# APP_ECC_AGG register map
Vendor: Texas Instruments
Peripheral module from a debugger description file (folder xwrl64xx).
Registers are 32-bit, access per field, no defined reset value unless marked. A register's access mark holds for its fields unless they carry their own. Offsets are as the file gives them; lines under a group give offsets from that group; [hi:lo] are bit positions; {n}, {i} and the like mark numbered series; 'fields as' and 'values as' point back to an identical list; <NAME> marks a mode.

## APP_ECC_AGG
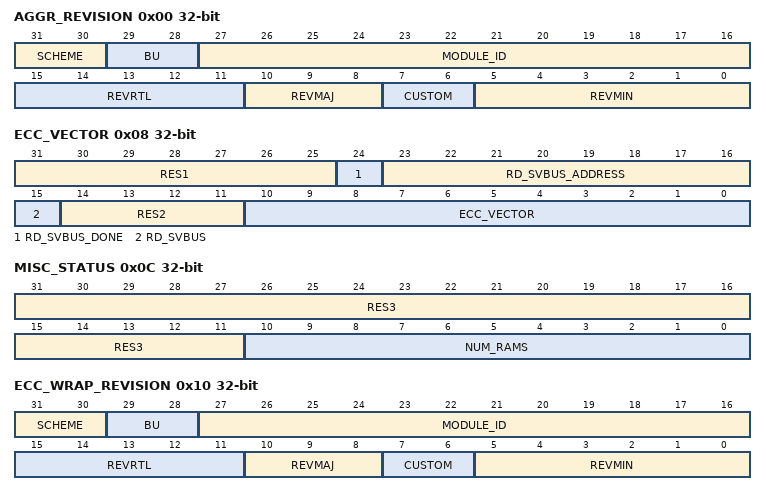
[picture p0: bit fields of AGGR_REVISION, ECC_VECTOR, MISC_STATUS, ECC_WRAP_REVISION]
0x00 AGGR_REVISION ro — Revision parameters
  [31:30] SCHEME — Scheme - (RO )
  [29:28] BU — bu - (RO )
  [27:16] MODULE_ID — Module ID - (RO )
  [15:11] REVRTL — RTL version - (RO )
  [10:8] REVMAJ — Major version - (RO )
  [7:6] CUSTOM — Custom version - (RO )
  [5:0] REVMIN — Minor version - (RO )
0x08 ECC_VECTOR
  [31:25] RES1 ro — RESERVE FIELD
  [24] RD_SVBUS_DONE ro — Status to indicate if read on serial VBUS is complete - (RO )
  [23:16] RD_SVBUS_ADDRESS rw — Read address - (RW )
  [15] RD_SVBUS rw — Write 1 to trigger a read on the serial VBUS - (RW )
  [14:11] RES2 ro — RESERVE FIELD
  [10:0] ECC_VECTOR rw — Value written to select the corresponding ECC RAM for control or status - (RW )
0x0C MISC_STATUS ro
  [31:11] RES3 — RESERVE FIELD
  [10:0] NUM_RAMS — Indicates the number of RAMS serviced by the ECC aggregator - (RO )
0x10 ECC_WRAP_REVISION ro — Revision parameters
  fields as AGGR_REVISION
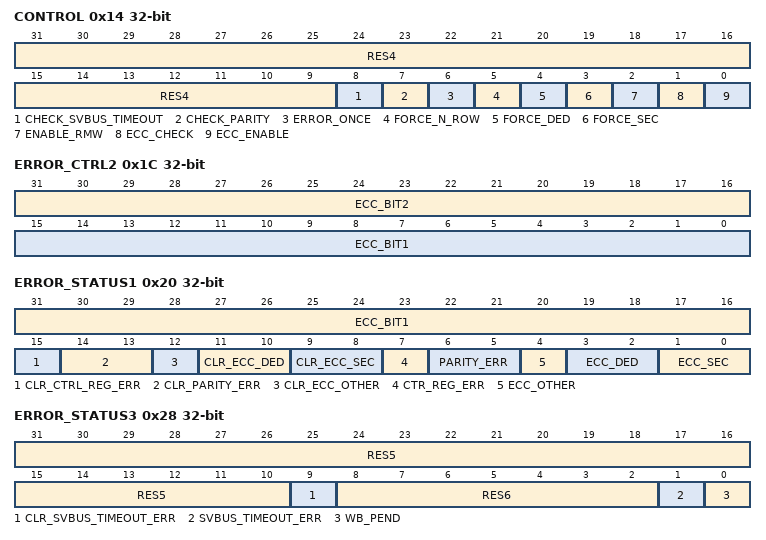
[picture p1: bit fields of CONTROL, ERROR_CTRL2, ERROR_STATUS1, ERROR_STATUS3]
0x14 CONTROL — ECC Control Register
  [31:9] RES4 ro — RESERVE FIELD
  [8] CHECK_SVBUS_TIMEOUT rw — check for svbus timeout errors - (RW )
  [7] CHECK_PARITY rw — check for parity errors - (RW )
  [6] ERROR_ONCE rw — Force Error only once - (RW )
  [5] FORCE_N_ROW rw — Force Error on any RAM read - (RW )
  [4] FORCE_DED rw — Force Double Bit Error - (RW )
  [3] FORCE_SEC rw — Force Single Bit Error - (RW )
  [2] ENABLE_RMW rw — Enable rmw - (RW )
  [1] ECC_CHECK rw — Enable ECC check - (RW )
  [0] ECC_ENABLE rw — Enable ECC - (RW )
0x18 ERROR_CTRL1 rw — ECC Error Control1 Register
  [31:0] ECC_ROW — Row address where single or double-bit error needs to be applied. This is ignored if force_n_row is set - (RW )
0x1C ERROR_CTRL2 rw — ECC Error Control2 Register
  [31:16] ECC_BIT2 — Data bit that needs to be flipped if double bit error needs to be forced - (RW )
  [15:0] ECC_BIT1 — Data bit that needs to be flipped when force_sec is set - (RW )
0x20 ERROR_STATUS1 — ECC Error Status1 Register
  [31:16] ECC_BIT1 ro — Data bit that corresponds to the single-bit error - (RO )
  [15] CLR_CTRL_REG_ERR rw — Clear control reg error Error Status you must also re write the contorl ergister itself to clear this - (RW )
  [14:13] CLR_PARITY_ERR rw — Clear parity Error Status - (RW decr)
  [12] CLR_ECC_OTHER rw — Clear other Error Status - (RW )
  [11:10] CLR_ECC_DED rw — Clear Double Bit Error Status - (RW decr)
  [9:8] CLR_ECC_SEC rw — Clear Single Bit Error Status - (RW decr)
  [7] CTR_REG_ERR rw — control register error pending Level interrupt - (RW
  [6:5] PARITY_ERR rw — Level parity error Error Status - (RW )
  [4] ECC_OTHER rw — successive single-bit errors have occurred while a writeback is still pending Level interrupt - (RW
  [3:2] ECC_DED rw — Level Double Bit Error Status - (RW incr)
  [1:0] ECC_SEC rw — Level Single Bit Error Status - (RW incr)
0x24 ERROR_STATUS2 ro — ECC Error Status2 Register
  [31:0] ECC_ROW — Row address where the single or double-bit error has occurred - (RO )
0x28 ERROR_STATUS3 — ECC Error Status3 Register
  [31:10] RES5 ro — RESERVE FIELD
  [9] CLR_SVBUS_TIMEOUT_ERR rw — Clear svbus timeout Error Status - (RW )
  [8:2] RES6 ro — RESERVE FIELD
  [1] SVBUS_TIMEOUT_ERR rw — Level svbus timeout error Error Status - (RW )
  [0] WB_PEND ro — delayed write back pending Status - (RO )
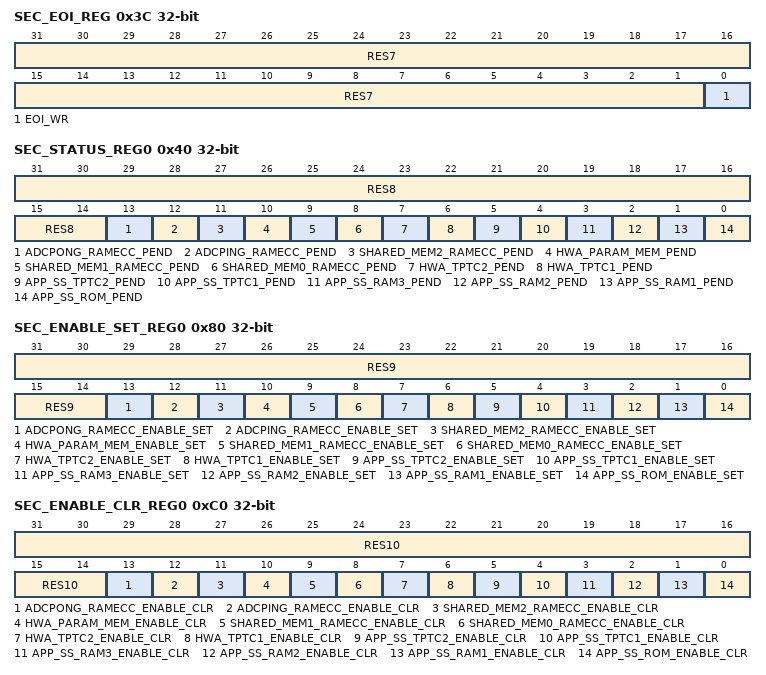
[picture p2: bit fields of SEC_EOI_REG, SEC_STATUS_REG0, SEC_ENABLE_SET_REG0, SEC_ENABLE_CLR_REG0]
0x3C SEC_EOI_REG — EOI Register
  [31:1] RES7 ro — RESERVE FIELD
  [0] EOI_WR rw — EOI Register - (RW )
0x40 SEC_STATUS_REG0 — Interrupt Status Register 0
  [31:14] RES8 ro — RESERVE FIELD
  [13] ADCPONG_RAMECC_PEND rw — Interrupt Pending Status for adcpong_ramecc_pend - (RW )
  [12] ADCPING_RAMECC_PEND rw — Interrupt Pending Status for adcping_ramecc_pend - (RW )
  [11] SHARED_MEM2_RAMECC_PEND rw — Interrupt Pending Status for shared_mem2_ramecc_pend - (RW )
  [10] HWA_PARAM_MEM_PEND rw — Interrupt Pending Status for hwa_param_mem_pend - (RW )
  [9] SHARED_MEM1_RAMECC_PEND rw — Interrupt Pending Status for shared_mem1_ramecc_pend - (RW )
  [8] SHARED_MEM0_RAMECC_PEND rw — Interrupt Pending Status for shared_mem0_ramecc_pend - (RW )
  [7] HWA_TPTC2_PEND rw — Interrupt Pending Status for hwa_tptc2_pend - (RW )
  [6] HWA_TPTC1_PEND rw — Interrupt Pending Status for hwa_tptc1_pend - (RW )
  [5] APP_SS_TPTC2_PEND rw — Interrupt Pending Status for app_ss_tptc2_pend - (RW )
  [4] APP_SS_TPTC1_PEND rw — Interrupt Pending Status for app_ss_tptc1_pend - (RW )
  [3] APP_SS_RAM3_PEND rw — Interrupt Pending Status for app_ss_ram3_pend - (RW )
  [2] APP_SS_RAM2_PEND rw — Interrupt Pending Status for app_ss_ram2_pend - (RW )
  [1] APP_SS_RAM1_PEND rw — Interrupt Pending Status for app_ss_ram1_pend - (RW )
  [0] APP_SS_ROM_PEND rw — Interrupt Pending Status for app_ss_rom_pend - (RW )
0x80 SEC_ENABLE_SET_REG0 — Interrupt Enable Set Register 0
  [31:14] RES9 ro — RESERVE FIELD
  [13] ADCPONG_RAMECC_ENABLE_SET rw — Interrupt Enable Set Register for adcpong_ramecc_pend - (RW )
  [12] ADCPING_RAMECC_ENABLE_SET rw — Interrupt Enable Set Register for adcping_ramecc_pend - (RW )
  [11] SHARED_MEM2_RAMECC_ENABLE_SET rw — Interrupt Enable Set Register for shared_mem2_ramecc_pend - (RW )
  [10] HWA_PARAM_MEM_ENABLE_SET rw — Interrupt Enable Set Register for hwa_param_mem_pend - (RW )
  [9] SHARED_MEM1_RAMECC_ENABLE_SET rw — Interrupt Enable Set Register for shared_mem1_ramecc_pend - (RW )
  [8] SHARED_MEM0_RAMECC_ENABLE_SET rw — Interrupt Enable Set Register for shared_mem0_ramecc_pend - (RW )
  [7] HWA_TPTC2_ENABLE_SET rw — Interrupt Enable Set Register for hwa_tptc2_pend - (RW )
  [6] HWA_TPTC1_ENABLE_SET rw — Interrupt Enable Set Register for hwa_tptc1_pend - (RW )
  [5] APP_SS_TPTC2_ENABLE_SET rw — Interrupt Enable Set Register for app_ss_tptc2_pend - (RW )
  [4] APP_SS_TPTC1_ENABLE_SET rw — Interrupt Enable Set Register for app_ss_tptc1_pend - (RW )
  [3] APP_SS_RAM3_ENABLE_SET rw — Interrupt Enable Set Register for app_ss_ram3_pend - (RW )
  [2] APP_SS_RAM2_ENABLE_SET rw — Interrupt Enable Set Register for app_ss_ram2_pend - (RW )
  [1] APP_SS_RAM1_ENABLE_SET rw — Interrupt Enable Set Register for app_ss_ram1_pend - (RW )
  [0] APP_SS_ROM_ENABLE_SET rw — Interrupt Enable Set Register for app_ss_rom_pend - (RW )
0xC0 SEC_ENABLE_CLR_REG0 — Interrupt Enable Clear Register 0
  [31:14] RES10 ro — RESERVE FIELD
  [13] ADCPONG_RAMECC_ENABLE_CLR rw — Interrupt Enable Clear Register for adcpong_ramecc_pend - (RW )
  [12] ADCPING_RAMECC_ENABLE_CLR rw — Interrupt Enable Clear Register for adcping_ramecc_pend - (RW )
  [11] SHARED_MEM2_RAMECC_ENABLE_CLR rw — Interrupt Enable Clear Register for shared_mem2_ramecc_pend - (RW )
  [10] HWA_PARAM_MEM_ENABLE_CLR rw — Interrupt Enable Clear Register for hwa_param_mem_pend - (RW )
  [9] SHARED_MEM1_RAMECC_ENABLE_CLR rw — Interrupt Enable Clear Register for shared_mem1_ramecc_pend - (RW )
  [8] SHARED_MEM0_RAMECC_ENABLE_CLR rw — Interrupt Enable Clear Register for shared_mem0_ramecc_pend - (RW )
  [7] HWA_TPTC2_ENABLE_CLR rw — Interrupt Enable Clear Register for hwa_tptc2_pend - (RW )
  [6] HWA_TPTC1_ENABLE_CLR rw — Interrupt Enable Clear Register for hwa_tptc1_pend - (RW )
  [5] APP_SS_TPTC2_ENABLE_CLR rw — Interrupt Enable Clear Register for app_ss_tptc2_pend - (RW )
  [4] APP_SS_TPTC1_ENABLE_CLR rw — Interrupt Enable Clear Register for app_ss_tptc1_pend - (RW )
  [3] APP_SS_RAM3_ENABLE_CLR rw — Interrupt Enable Clear Register for app_ss_ram3_pend - (RW )
  [2] APP_SS_RAM2_ENABLE_CLR rw — Interrupt Enable Clear Register for app_ss_ram2_pend - (RW )
  [1] APP_SS_RAM1_ENABLE_CLR rw — Interrupt Enable Clear Register for app_ss_ram1_pend - (RW )
  [0] APP_SS_ROM_ENABLE_CLR rw — Interrupt Enable Clear Register for app_ss_rom_pend - (RW )
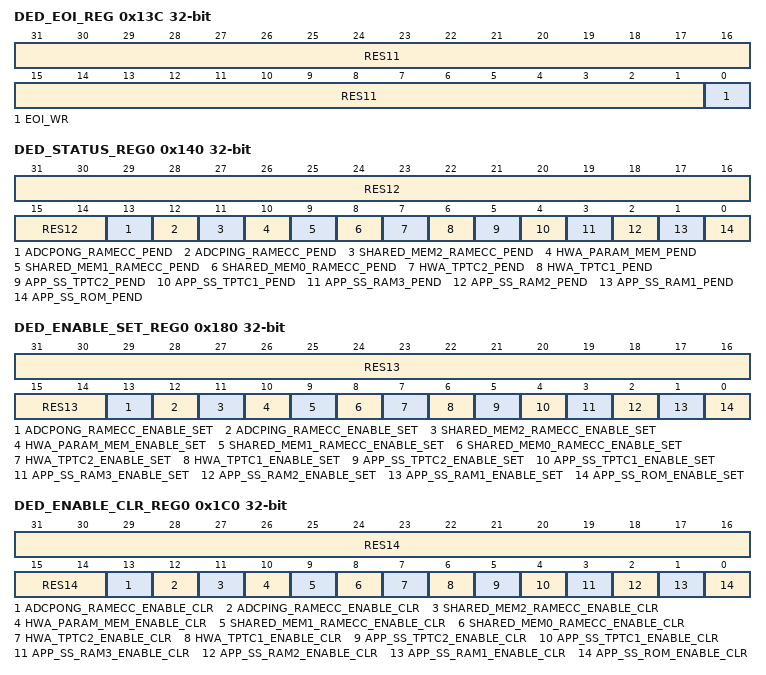
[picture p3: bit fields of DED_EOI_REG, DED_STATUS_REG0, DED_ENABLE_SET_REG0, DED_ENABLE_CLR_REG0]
0x13C DED_EOI_REG — EOI Register
  [31:1] RES11 ro — RESERVE FIELD
  [0] EOI_WR rw — EOI Register - (RW )
0x140 DED_STATUS_REG0 — Interrupt Status Register 0
  [31:14] RES12 ro — RESERVE FIELD
  [13] ADCPONG_RAMECC_PEND rw — Interrupt Pending Status for adcpong_ramecc_pend - (RW )
  [12] ADCPING_RAMECC_PEND rw — Interrupt Pending Status for adcping_ramecc_pend - (RW )
  [11] SHARED_MEM2_RAMECC_PEND rw — Interrupt Pending Status for shared_mem2_ramecc_pend - (RW )
  [10] HWA_PARAM_MEM_PEND rw — Interrupt Pending Status for hwa_param_mem_pend - (RW )
  [9] SHARED_MEM1_RAMECC_PEND rw — Interrupt Pending Status for shared_mem1_ramecc_pend - (RW )
  [8] SHARED_MEM0_RAMECC_PEND rw — Interrupt Pending Status for shared_mem0_ramecc_pend - (RW )
  [7] HWA_TPTC2_PEND rw — Interrupt Pending Status for hwa_tptc2_pend - (RW )
  [6] HWA_TPTC1_PEND rw — Interrupt Pending Status for hwa_tptc1_pend - (RW )
  [5] APP_SS_TPTC2_PEND rw — Interrupt Pending Status for app_ss_tptc2_pend - (RW )
  [4] APP_SS_TPTC1_PEND rw — Interrupt Pending Status for app_ss_tptc1_pend - (RW )
  [3] APP_SS_RAM3_PEND rw — Interrupt Pending Status for app_ss_ram3_pend - (RW )
  [2] APP_SS_RAM2_PEND rw — Interrupt Pending Status for app_ss_ram2_pend - (RW )
  [1] APP_SS_RAM1_PEND rw — Interrupt Pending Status for app_ss_ram1_pend - (RW )
  [0] APP_SS_ROM_PEND rw — Interrupt Pending Status for app_ss_rom_pend - (RW )
0x180 DED_ENABLE_SET_REG0 — Interrupt Enable Set Register 0
  [31:14] RES13 ro — RESERVE FIELD
  [13] ADCPONG_RAMECC_ENABLE_SET rw — Interrupt Enable Set Register for adcpong_ramecc_pend - (RW )
  [12] ADCPING_RAMECC_ENABLE_SET rw — Interrupt Enable Set Register for adcping_ramecc_pend - (RW )
  [11] SHARED_MEM2_RAMECC_ENABLE_SET rw — Interrupt Enable Set Register for shared_mem2_ramecc_pend - (RW )
  [10] HWA_PARAM_MEM_ENABLE_SET rw — Interrupt Enable Set Register for hwa_param_mem_pend - (RW )
  [9] SHARED_MEM1_RAMECC_ENABLE_SET rw — Interrupt Enable Set Register for shared_mem1_ramecc_pend - (RW )
  [8] SHARED_MEM0_RAMECC_ENABLE_SET rw — Interrupt Enable Set Register for shared_mem0_ramecc_pend - (RW )
  [7] HWA_TPTC2_ENABLE_SET rw — Interrupt Enable Set Register for hwa_tptc2_pend - (RW )
  [6] HWA_TPTC1_ENABLE_SET rw — Interrupt Enable Set Register for hwa_tptc1_pend - (RW )
  [5] APP_SS_TPTC2_ENABLE_SET rw — Interrupt Enable Set Register for app_ss_tptc2_pend - (RW )
  [4] APP_SS_TPTC1_ENABLE_SET rw — Interrupt Enable Set Register for app_ss_tptc1_pend - (RW )
  [3] APP_SS_RAM3_ENABLE_SET rw — Interrupt Enable Set Register for app_ss_ram3_pend - (RW )
  [2] APP_SS_RAM2_ENABLE_SET rw — Interrupt Enable Set Register for app_ss_ram2_pend - (RW )
  [1] APP_SS_RAM1_ENABLE_SET rw — Interrupt Enable Set Register for app_ss_ram1_pend - (RW )
  [0] APP_SS_ROM_ENABLE_SET rw — Interrupt Enable Set Register for app_ss_rom_pend - (RW )
0x1C0 DED_ENABLE_CLR_REG0 — Interrupt Enable Clear Register 0
  [31:14] RES14 ro — RESERVE FIELD
  [13] ADCPONG_RAMECC_ENABLE_CLR rw — Interrupt Enable Clear Register for adcpong_ramecc_pend - (RW )
  [12] ADCPING_RAMECC_ENABLE_CLR rw — Interrupt Enable Clear Register for adcping_ramecc_pend - (RW )
  [11] SHARED_MEM2_RAMECC_ENABLE_CLR rw — Interrupt Enable Clear Register for shared_mem2_ramecc_pend - (RW )
  [10] HWA_PARAM_MEM_ENABLE_CLR rw — Interrupt Enable Clear Register for hwa_param_mem_pend - (RW )
  [9] SHARED_MEM1_RAMECC_ENABLE_CLR rw — Interrupt Enable Clear Register for shared_mem1_ramecc_pend - (RW )
  [8] SHARED_MEM0_RAMECC_ENABLE_CLR rw — Interrupt Enable Clear Register for shared_mem0_ramecc_pend - (RW )
  [7] HWA_TPTC2_ENABLE_CLR rw — Interrupt Enable Clear Register for hwa_tptc2_pend - (RW )
  [6] HWA_TPTC1_ENABLE_CLR rw — Interrupt Enable Clear Register for hwa_tptc1_pend - (RW )
  [5] APP_SS_TPTC2_ENABLE_CLR rw — Interrupt Enable Clear Register for app_ss_tptc2_pend - (RW )
  [4] APP_SS_TPTC1_ENABLE_CLR rw — Interrupt Enable Clear Register for app_ss_tptc1_pend - (RW )
  [3] APP_SS_RAM3_ENABLE_CLR rw — Interrupt Enable Clear Register for app_ss_ram3_pend - (RW )
  [2] APP_SS_RAM2_ENABLE_CLR rw — Interrupt Enable Clear Register for app_ss_ram2_pend - (RW )
  [1] APP_SS_RAM1_ENABLE_CLR rw — Interrupt Enable Clear Register for app_ss_ram1_pend - (RW )
  [0] APP_SS_ROM_ENABLE_CLR rw — Interrupt Enable Clear Register for app_ss_rom_pend - (RW )
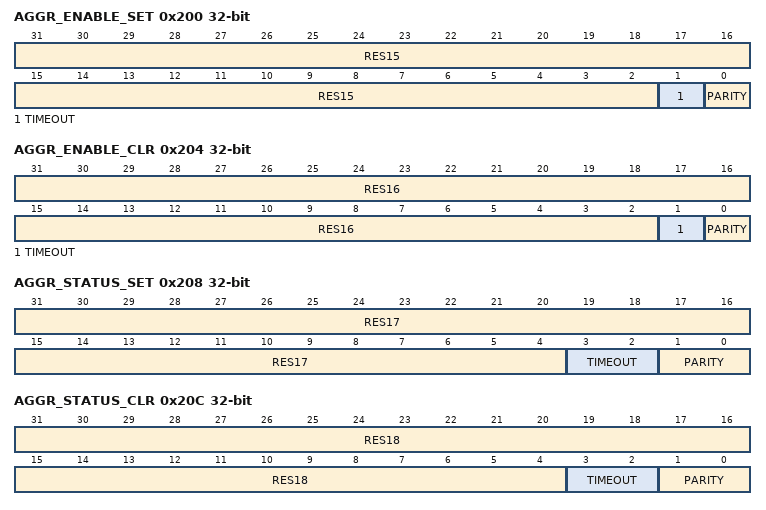
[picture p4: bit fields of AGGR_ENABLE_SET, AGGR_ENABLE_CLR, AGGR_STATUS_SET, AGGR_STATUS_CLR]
0x200 AGGR_ENABLE_SET — AGGR interrupt enable set Register
  [31:2] RES15 ro — RESERVE FIELD
  [1] TIMEOUT rw — interrupt enable set for svbus timeout errors - (RW )
  [0] PARITY rw — interrupt enable set for parity errors - (RW )
0x204 AGGR_ENABLE_CLR — AGGR interrupt enable clear Register
  [31:2] RES16 ro — RESERVE FIELD
  [1] TIMEOUT rw — interrupt enable clear for svbus timeout errors - (RW )
  [0] PARITY rw — interrupt enable clear for parity errors - (RW )
0x208 AGGR_STATUS_SET — AGGR interrupt status set Register
  [31:4] RES17 ro — RESERVE FIELD
  [3:2] TIMEOUT rw — interrupt status set for svbus timeout errors - (RW incr)
  [1:0] PARITY rw — interrupt status set for parity errors - (RW incr)
0x20C AGGR_STATUS_CLR — AGGR interrupt status clear Register
  [31:4] RES18 ro — RESERVE FIELD
  [3:2] TIMEOUT rw — interrupt status clear for svbus timeout errors - (RW decr)
  [1:0] PARITY rw — interrupt status clear for parity errors - (RW decr)
